# HSI_TOP register map
Vendor: Texas Instruments
Peripheral module from a debugger description file (folder omap5430_ES2_PUBLIC).
Registers are 32-bit, access per field, reset 0x0 unless marked. A register's access mark holds for its fields unless they carry their own. Offsets are as the file gives them; lines under a group give offsets from that group; [hi:lo] are bit positions; {n}, {i} and the like mark numbered series; 'fields as' and 'values as' point back to an identical list; <NAME> marks a mode.

## HSI_TOP
0x00 HSI_REVISION ro reset not defined — IP Revision Identifier (X.Y.R) Used by software to track features, bugs, and compatibility
  [31:0] REVISION — IP Revision
0x04 HSI_HWINFO ro reset not defined — Information about the IP module hardware configuration, that is, typically the module HDL generics (if any). Actual field format and encoding is decided by the module designer.
  [31:0] HWINFO — IP module hardware configuration
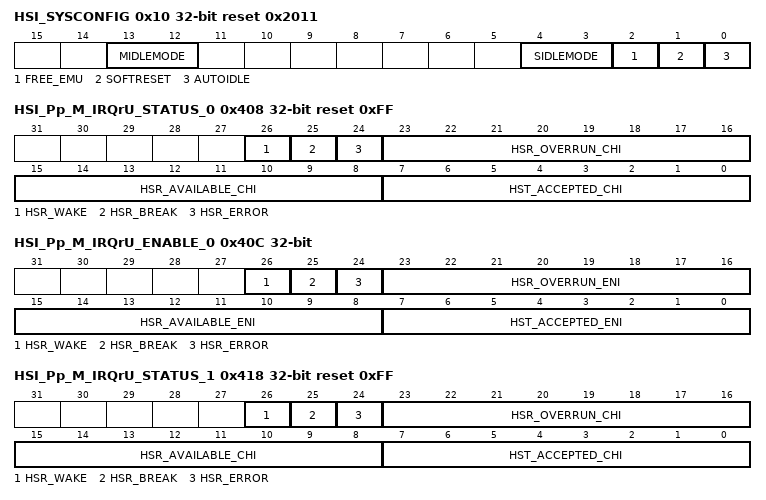
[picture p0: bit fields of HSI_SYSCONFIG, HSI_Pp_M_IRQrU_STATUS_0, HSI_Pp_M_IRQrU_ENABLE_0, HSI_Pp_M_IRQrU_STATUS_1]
0x10 HSI_SYSCONFIG reset 0x2011 — This register allows controlling various parameters of the L4_CFG interface
  [13:12] MIDLEMODE rw — Master interface power management, standby/wait control
    0=Force-standby; 1=No-standby; 2=Smart-standby; 3=Smart-standby_wakeup
  [4:3] SIDLEMODE rw — Slave interface power management, request/acknowledgment control
    0=Force-idle; 1=No-idle; 2=Smart-idle; 3=Smart-idle_wakeup
  [2] FREE_EMU rw — Sensitivity to emulation (debug) suspend input signal
    0=Module is sensitive to emulation suspend; 1=Module is not sensitive to emulation suspend
  [1] SOFTRESET rw — Software reset
  [0] AUTOIDLE rw — Internal interface clock gating strategy
    0=Interface_clock_is_free-running; 1=Automatic interface clock gating strategy, based on interconnect interface activity
0x14 HSI_SYSSTATUS ro reset 0x1 — Status on module (reset done on bit 0, available for more status information)
  [31:0] RESETDONE — internal reset monitoring
    0=Internal_reset_is_ongoing; 1=RESETDONE_1_r (Internal reset is completed and the module is ready to be used.)
0x408 HSI_Pp_M_IRQrU_STATUS_0 reset 0xFF — IRQ status register for FIFO (8..15) events and for port p break, wake and error events. Events will signal interrupt for MPU line r (Mpuirq_r). Read 0: Event has not occurred. Read 1: Event has occurred. Write 0: Bit stays unchanged. Write 1: Bit is reset to 0.
  [26] HSR_WAKE rw — Wake detected on any channel 8..15
  [25] HSR_BREAK rw — Break detected on any channel 8..15
  [24] HSR_ERROR rw — Error detected on any channel 8..15
  [23:16] HSR_OVERRUN_CHI rw — Data overrun in real-time mode channel 8..15 (LSB stands for channel 8 and MSB for channel 15).
  [15:8] HSR_AVAILABLE_CHI rw — Data received on channel 8..15 (LSB stands for channel 8 and MSB for channel 15). The status bit shows data on the respective channel, while there are data in the FIFO. Clearing the status bit has no effect, while the FIFO is not empty.
  [7:0] HST_ACCEPTED_CHI rw — Data transmitted on channel 8..15 (LSB stands for channel 8 and MSB for channel 15)
0x40C HSI_Pp_M_IRQrU_ENABLE_0 — IRQ enable register for FIFO (8..15) events and for port p break, wake and error events signaled to MPU line r (Mpuirq_r). Write 0: Event is masked. Write 1: Event is enabled.
  [26] HSR_WAKE rw — Wake interrupt enable for all channels 8..15
  [25] HSR_BREAK rw — Break interrupt enable for all channels 8..15
  [24] HSR_ERROR rw — Error interrupt enable for all channels 8..15
  [23:16] HSR_OVERRUN_ENI rw — Overrun interrupt enable for channel 8..15 (LSB stands for channel 8 and MSB for channel 15)
  [15:8] HSR_AVAILABLE_ENI rw — Data available interrupt enable for channel 8..15 (LSB stands for channel 8 and MSB for channel 15)
  [7:0] HST_ACCEPTED_ENI rw — Data accepted interrupt enable for channel 8..15 (LSB stands for channel 8 and MSB for channel 15)
0x418 HSI_Pp_M_IRQrU_STATUS_1 reset 0xFF — IRQ status register for FIFO (8..15) events and for port p break, wake and error events. Events will signal interrupt for MPU line r (Mpuirq_r). Read 0: Event has not occurred. Read 1: Event has occurred. Write 0: Bit stays unchanged. Write 1: Bit is reset to 0.
  fields as HSI_Pp_M_IRQrU_STATUS_0
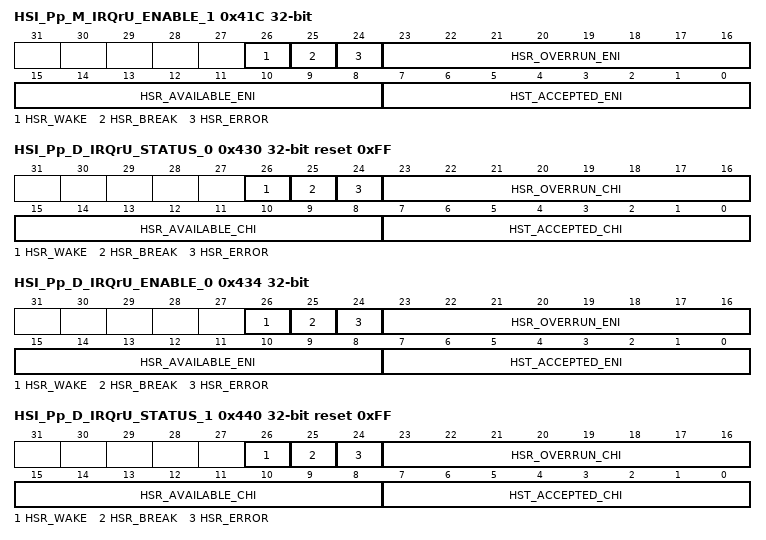
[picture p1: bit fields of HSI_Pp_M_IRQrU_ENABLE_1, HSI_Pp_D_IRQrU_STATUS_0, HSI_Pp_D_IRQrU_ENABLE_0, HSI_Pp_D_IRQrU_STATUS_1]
0x41C HSI_Pp_M_IRQrU_ENABLE_1 — IRQ enable register for FIFO (8..15) events and for port p break, wake and error events signaled to MPU line r (Mpuirq_r). Write 0: Event is masked. Write 1: Event is enabled.
  fields as HSI_Pp_M_IRQrU_ENABLE_0
0x430 HSI_Pp_D_IRQrU_STATUS_0 reset 0xFF — IRQ status register for FIFO (8..15) events and for port p break, wake and error events. Events will signal interrupt for DSP line r (Dspirq_r). Read 0: Event has not occurred. Read 1: Event has occurred. Write 0: Bit stays unchanged. Write 1: Bit is reset to 0.
  [26] HSR_WAKE rw — Wake detected on any channel 8..15
  [25] HSR_BREAK rw — Break detected on any channel 8..15
  [24] HSR_ERROR rw — Error on any channel 8..15
  [23:16] HSR_OVERRUN_CHI rw — Data overrun in real-time mode channel 8..15 (LSB stands for channel 8 and MSB for channel 15)
  [15:8] HSR_AVAILABLE_CHI rw — Data received on channel 8..15 (LSB stands for channel 8 and MSB for channel 15). The status bit shows data on the respective channel, while there are data in the FIFO. Clearing the status bit has no effect, while the FIFO is not empty.
  [7:0] HST_ACCEPTED_CHI rw — Data transmitted on channel 8..15 (LSB stands for channel 8 and MSB for channel 15)
0x434 HSI_Pp_D_IRQrU_ENABLE_0 — IRQ enable register for FIFO (8..15) events and for port p break, wake and error events signaled to DSP line r (Dspirq_r). Write 0: Event is masked. Write 1:Eevent is enabled.
  [26] HSR_WAKE rw — Wake interrupt enable for channel 8..15
  [25] HSR_BREAK rw — Break interrupt enable for channel 8..15
  [24] HSR_ERROR rw — Error interrupt enable for channel 8..15
  [23:16] HSR_OVERRUN_ENI rw — Overrun interrupt enable for channel 8..15
  [15:8] HSR_AVAILABLE_ENI rw — Data available interrupt enable for channel 8..15 (LSB stands for channel 8 and MSB for channel 15)
  [7:0] HST_ACCEPTED_ENI rw — Data accepted interrupt enable for channel 8..15 (LSB stands for channel 8 and MSB for channel 15)
0x440 HSI_Pp_D_IRQrU_STATUS_1 reset 0xFF — IRQ status register for FIFO (8..15) events and for port p break, wake and error events. Events will signal interrupt for DSP line r (Dspirq_r). Read 0: Event has not occurred. Read 1: Event has occurred. Write 0: Bit stays unchanged. Write 1: Bit is reset to 0.
  fields as HSI_Pp_D_IRQrU_STATUS_0
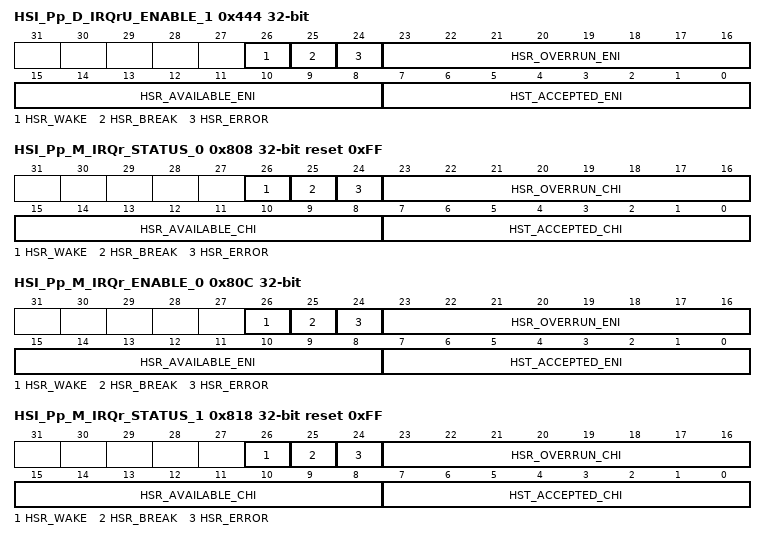
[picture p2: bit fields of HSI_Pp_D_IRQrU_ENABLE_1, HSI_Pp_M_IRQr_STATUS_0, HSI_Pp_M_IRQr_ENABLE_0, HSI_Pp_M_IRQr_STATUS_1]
0x444 HSI_Pp_D_IRQrU_ENABLE_1 — IRQ enable register for FIFO (8..15) events and for port p break, wake and error events signaled to DSP line r (Dspirq_r). Write 0: Event is masked. Write 1:Eevent is enabled.
  fields as HSI_Pp_D_IRQrU_ENABLE_0
0x800 HSI_DMA_M_IRQSTATUS — This register collects status for all of the DMA events able to generate interrupt to MPU: Read 0: Event has not occurred. Read 1: Event has occurred. Write 0: Bit stays unchanged. Write 1: Bit is reset to 0.
  [15:0] DMA_CHI rw — Channel 0..15 status (LSB stands for channel 0 and MSB for channel 15)
0x804 HSI_DMA_M_IRQENABLE — This register masks and unmasks DMA sources of interrupt to MPU: Write 0: event is masked Write 1: event is enabled
  [15:0] DMA_EN_CHI rw — Channel 0..15 status (LSB stands for channel 0 and MSB for channel 15)
0x808 HSI_Pp_M_IRQr_STATUS_0 reset 0xFF — IRQ status register for FIFO (0..7) events and for port p break, wake and error events. Events will signal interrupt for MPU line r (Mpuirq_r). Read 0: Event has not occurred. Read 1: Event has occurred. Write 0: Bit stays unchanged. Write 1: Bit is reset to 0.
  [26] HSR_WAKE rw — Wake detected on Port p
  [25] HSR_BREAK rw — Break detected on Port p
  [24] HSR_ERROR rw — Error on Port p
  [23:16] HSR_OVERRUN_CHI rw — Data overrun in real time mode channel 0..7 (LSB stands for channel 0 and MSB for channel 7)
  [15:8] HSR_AVAILABLE_CHI rw — Data received on channel 0..7 (LSB stands for channel 0 and MSB for channel 7). The status bit shows data on the respective channel, while there are data in the FIFO. Clearing the status bit has no effect, while the FIFO is not empty.
  [7:0] HST_ACCEPTED_CHI rw — Data transmitted on channel 0..7 (LSB stands for channel 0 and MSB for channel 7)
0x80C HSI_Pp_M_IRQr_ENABLE_0 — IRQ enable register for FIFO (0..7) events and for port p break, wake and error events signaled to MPU line r (Mpuirq_r). Write 0: Event is masked. Write 1: Event is enabled.
  [26] HSR_WAKE rw — Wake interrupt enable for Port p
  [25] HSR_BREAK rw — Break interrupt enable for Port p
  [24] HSR_ERROR rw — Error interrupt enable for Port p
  [23:16] HSR_OVERRUN_ENI rw — Overrun interrupt enable for channel 0..7 (LSB stands for channel 0 and MSB for channel 7)
  [15:8] HSR_AVAILABLE_ENI rw — Data available interrupt enable for channel 0..7 (LSB stands for channel 0 and MSB for channel 7)
  [7:0] HST_ACCEPTED_ENI rw — Data accepted interrupt enable for channel 0..7 (LSB stands for channel 0 and MSB for channel 7)
0x818 HSI_Pp_M_IRQr_STATUS_1 reset 0xFF — IRQ status register for FIFO (0..7) events and for port p break, wake and error events. Events will signal interrupt for MPU line r (Mpuirq_r). Read 0: Event has not occurred. Read 1: Event has occurred. Write 0: Bit stays unchanged. Write 1: Bit is reset to 0.
  fields as HSI_Pp_M_IRQr_STATUS_0
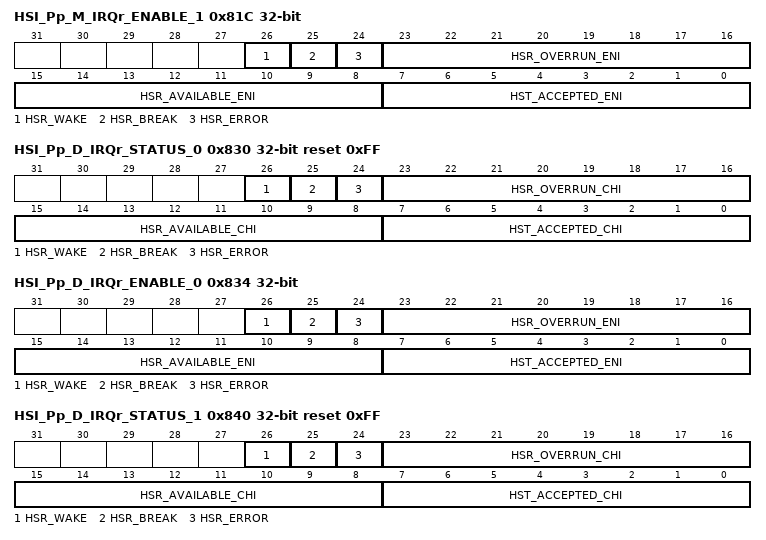
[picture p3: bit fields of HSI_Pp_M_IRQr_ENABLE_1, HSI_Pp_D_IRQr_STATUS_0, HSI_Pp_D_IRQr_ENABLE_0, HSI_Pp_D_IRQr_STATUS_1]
0x81C HSI_Pp_M_IRQr_ENABLE_1 — IRQ enable register for FIFO (0..7) events and for port p break, wake and error events signaled to MPU line r (Mpuirq_r). Write 0: Event is masked. Write 1: Event is enabled.
  fields as HSI_Pp_M_IRQr_ENABLE_0
0x828 HSI_DMA_D_IRQSTATUS — IRQ status register for all DMA events. Events generate interrupt for DSP. Read 0: Event has not occurred; Read 1: Event has occurred ; Write 0: Bit stays unchanged; Write 1: Bit is reset to 0.
  [15:0] DMA_CHI rw — IRQ event happened on DMA channel 0..15 (LSB stands for channel 0 and MSB for channel 15).
0x82C HSI_DMA_D_IRQENABLE — IRQ enable register for all DMA events signaled to DSP. Write 0: Event is masked. Write 1: Event is enabled.
  [15:0] DMA_EN_CHI rw — Channel 0..15 (LSB stands for channel 0 and MSB for channel 15)
0x830 HSI_Pp_D_IRQr_STATUS_0 reset 0xFF — IRQ status register for FIFO (0..7) events and for port p break, wake and error events. Events will signal interrupt for DSP line r (Dspirq_r). Read 0: Event has not occurred. Read 1: Event has occurred. Write 0: Bit stays unchanged. Write 1: Bit is reset to 0.
  [26] HSR_WAKE rw — Wake detected on Port p
  [25] HSR_BREAK rw — Break detected on Port p
  [24] HSR_ERROR rw — Error on Port p
  [23:16] HSR_OVERRUN_CHI rw — Data overrun in real time mode channel 0..7 (LSB stands for channel 0 and MSB for channel 7)
  [15:8] HSR_AVAILABLE_CHI rw — Data received on channel 0..7 (LSB stands for channel 0 and MSB for channel 7). The status bit shows data on the respective channel, while there are data in the FIFO. Clearing the status bit has no effect, while the FIFO is not empty.
  [7:0] HST_ACCEPTED_CHI rw — Data transmitted on channel 0..7 (LSB stands for channel 0 and MSB for channel 7).
0x834 HSI_Pp_D_IRQr_ENABLE_0 — IRQ enable register for FIFO (0..7) events and for port p break, wake and error events signaled to DSP line r (Dspirq_r). Write 0: Event is masked. Write 1: Event is enabled.
  [26] HSR_WAKE rw — Wake interrupt enable for Port p
  [25] HSR_BREAK rw — Break interrupt enable for Port p
  [24] HSR_ERROR rw — Error interrupt enable for Port p
  [23:16] HSR_OVERRUN_ENI rw — Overrun interrupt enable for channel 0..7 (LSB stands for channel 0 and MSB for channel 7)
  [15:8] HSR_AVAILABLE_ENI rw — Data available interrupt enable for channel 0..7 (LSB stands for channel 0 and MSB for channel 7)
  [7:0] HST_ACCEPTED_ENI rw — Data accepted interrupt enable for channel 0..7 (LSB stands for channel 0 and MSB for channel 7).
0x840 HSI_Pp_D_IRQr_STATUS_1 reset 0xFF — IRQ status register for FIFO (0..7) events and for port p break, wake and error events. Events will signal interrupt for DSP line r (Dspirq_r). Read 0: Event has not occurred. Read 1: Event has occurred. Write 0: Bit stays unchanged. Write 1: Bit is reset to 0.
  fields as HSI_Pp_D_IRQr_STATUS_0
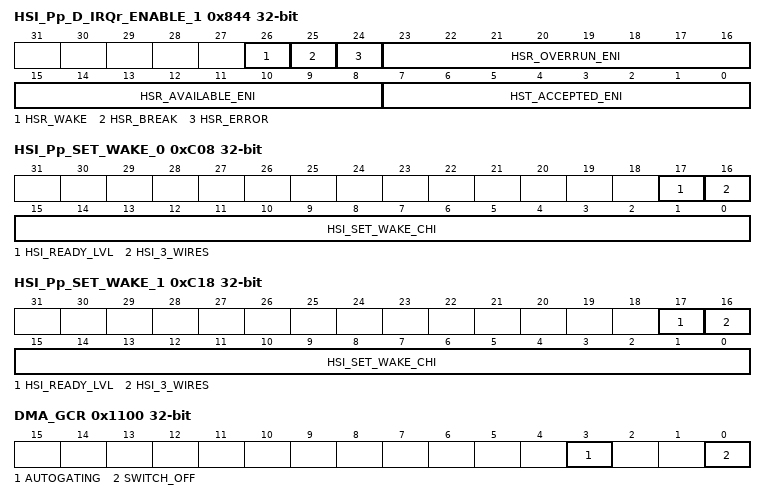
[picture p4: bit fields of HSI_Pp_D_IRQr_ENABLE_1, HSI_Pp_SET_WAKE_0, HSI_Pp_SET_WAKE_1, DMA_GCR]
0x844 HSI_Pp_D_IRQr_ENABLE_1 — IRQ enable register for FIFO (0..7) events and for port p break, wake and error events signaled to DSP line r (Dspirq_r). Write 0: Event is masked. Write 1: Event is enabled.
  fields as HSI_Pp_D_IRQr_ENABLE_0
0xC00 HSI_Pp_WAKE_0 ro — Programmed wake state for each channel, in port p 0x0: No channel wakeup on WAKE line requested. 0x1: Channel wakeup requested
  [15:0] HSI_WAKE_CHI — Channel 0..15 (LSB stands for channel 0 and MSB for channel 15)
0xC04 HSI_Pp_CLEAR_WAKE_0 — Clear register for programmed wake state on port p HST_WAKE for each channel 0x0: No effect 0x1: Clears bit
  [15:0] HSI_CLEAR_WAKE_CHI wo — Channel 0..15 (LSB stands for channel 0 and MSB for channel 15)
0xC08 HSI_Pp_SET_WAKE_0 — Set function for wake state for each channel, in port p 0x0: No effect 0x1: Sets bit
  [17] HSI_READY_LVL rw — READY default level
    0=READY_defaults_to_0; 1=READY_defaults_to_1
  [16] HSI_3_WIRES rw — Sets 3-wire behavior
    0=WAKE_0 (Sets 4-wire behavior (wakeup with WAKE signal)); 1=WAKE_1 (Sets 3-wire behavior (wakeup on line activity without WAKE signal))
  [15:0] HSI_SET_WAKE_CHI wo — Sets programmed WAKE state for channel i
    0=No_effect; 1=Sets_bit
0xC10 HSI_Pp_WAKE_1 ro — Programmed wake state for each channel, in port p 0x0: No channel wakeup on WAKE line requested. 0x1: Channel wakeup requested
  fields as HSI_Pp_WAKE_0
0xC14 HSI_Pp_CLEAR_WAKE_1 — Clear register for programmed wake state on port p HST_WAKE for each channel 0x0: No effect 0x1: Clears bit
  fields as HSI_Pp_CLEAR_WAKE_0
0xC18 HSI_Pp_SET_WAKE_1 — Set function for wake state for each channel, in port p 0x0: No effect 0x1: Sets bit
  fields as HSI_Pp_SET_WAKE_0
0x1100 DMA_GCR — Global Control Register: suspend and clock gating
  [3] AUTOGATING rw — DMA clock autogating enable
    0=No_DMA_clock_control; 1=DMA_clock_control
  [0] SWITCH_OFF rw — DMA global clock control
    0=DMA_clock_released; 1=DMA_clock_cutoff
0x1200 DMA_GRST — DMA software reset control register
  [0] SWRESET rw — DMA software reset control bit
    1=DMA._1 (Writing 1 resets the DMA. It is automatically reset to 0 by hardware once software reset is done.)
